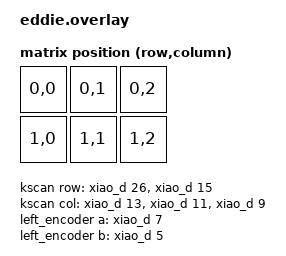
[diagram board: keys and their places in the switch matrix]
// This file was generated from a template. Edit it to match your keyboard.
// See https://zmk.dev/docs/development/hardware-integration/new-shield for more
// instructions.

#include <dt-bindings/zmk/matrix_transform.h>

#include "eddie-layouts.dtsi"

/ {
    chosen {
        zmk,physical-layout = &default_layout;
    };

    kscan: kscan {
        // If the hardware does not use a switch matrix, change this to the
        // appropriate driver and update the properties below to match.
        // See https://zmk.dev/docs/config/kscan for supported key scan drivers.
        compatible = "zmk,kscan-gpio-matrix";
        // Set this to "col2row" or "row2col" to match the hardware. If using
        // "row2col", change the col-gpios to (GPIO_ACTIVE_HIGH | GPIO_PULL_DOWN)
        // and the row-gpios to GPIO_ACTIVE_HIGH.
        diode-direction = "row2col";
        wakeup-source;

        // Replace these comments with the GPIO pins in the matrix.
        // See https://zmk.dev/docs/development/hardware-integration/new-shield#shield-overlays
        col-gpios
            = <&xiao_d 13 (GPIO_ACTIVE_HIGH | GPIO_PULL_DOWN)>
            , <&xiao_d 11 (GPIO_ACTIVE_HIGH | GPIO_PULL_DOWN)>
            , <&xiao_d 9 (GPIO_ACTIVE_HIGH | GPIO_PULL_DOWN)>
            ;

        row-gpios
            = <&xiao_d 26 GPIO_ACTIVE_HIGH>
            , <&xiao_d 15 GPIO_ACTIVE_HIGH>
            ;
    };

    left_encoder: encoder_left {
        compatible = "alps,ec11";
        label = "LEFT_ENCODER";
        a-gpios = <&xiao_d 7 (GPIO_ACTIVE_HIGH | GPIO_PULL_UP)>;
        b-gpios = <&xiao_d 5 (GPIO_ACTIVE_HIGH | GPIO_PULL_UP)>;
        resolution = <4>; // Use 20 for older/different methods, 4 is common for 20 pulse per 360deg with detents
        status = "okay";
    };

    default_transform: default_transform {
        // See https://zmk.dev/docs/development/hardware-integration/new-shield#matrix-transform
        // for how to configure this
        compatible = "zmk,matrix-transform";
        columns = <2>;
        rows = <2>;

        map = <
            RC(0, 0) RC(0, 1) RC(0, 2)
            RC(1, 0) RC(1, 1) RC(1, 2)
        >;
    };
};
